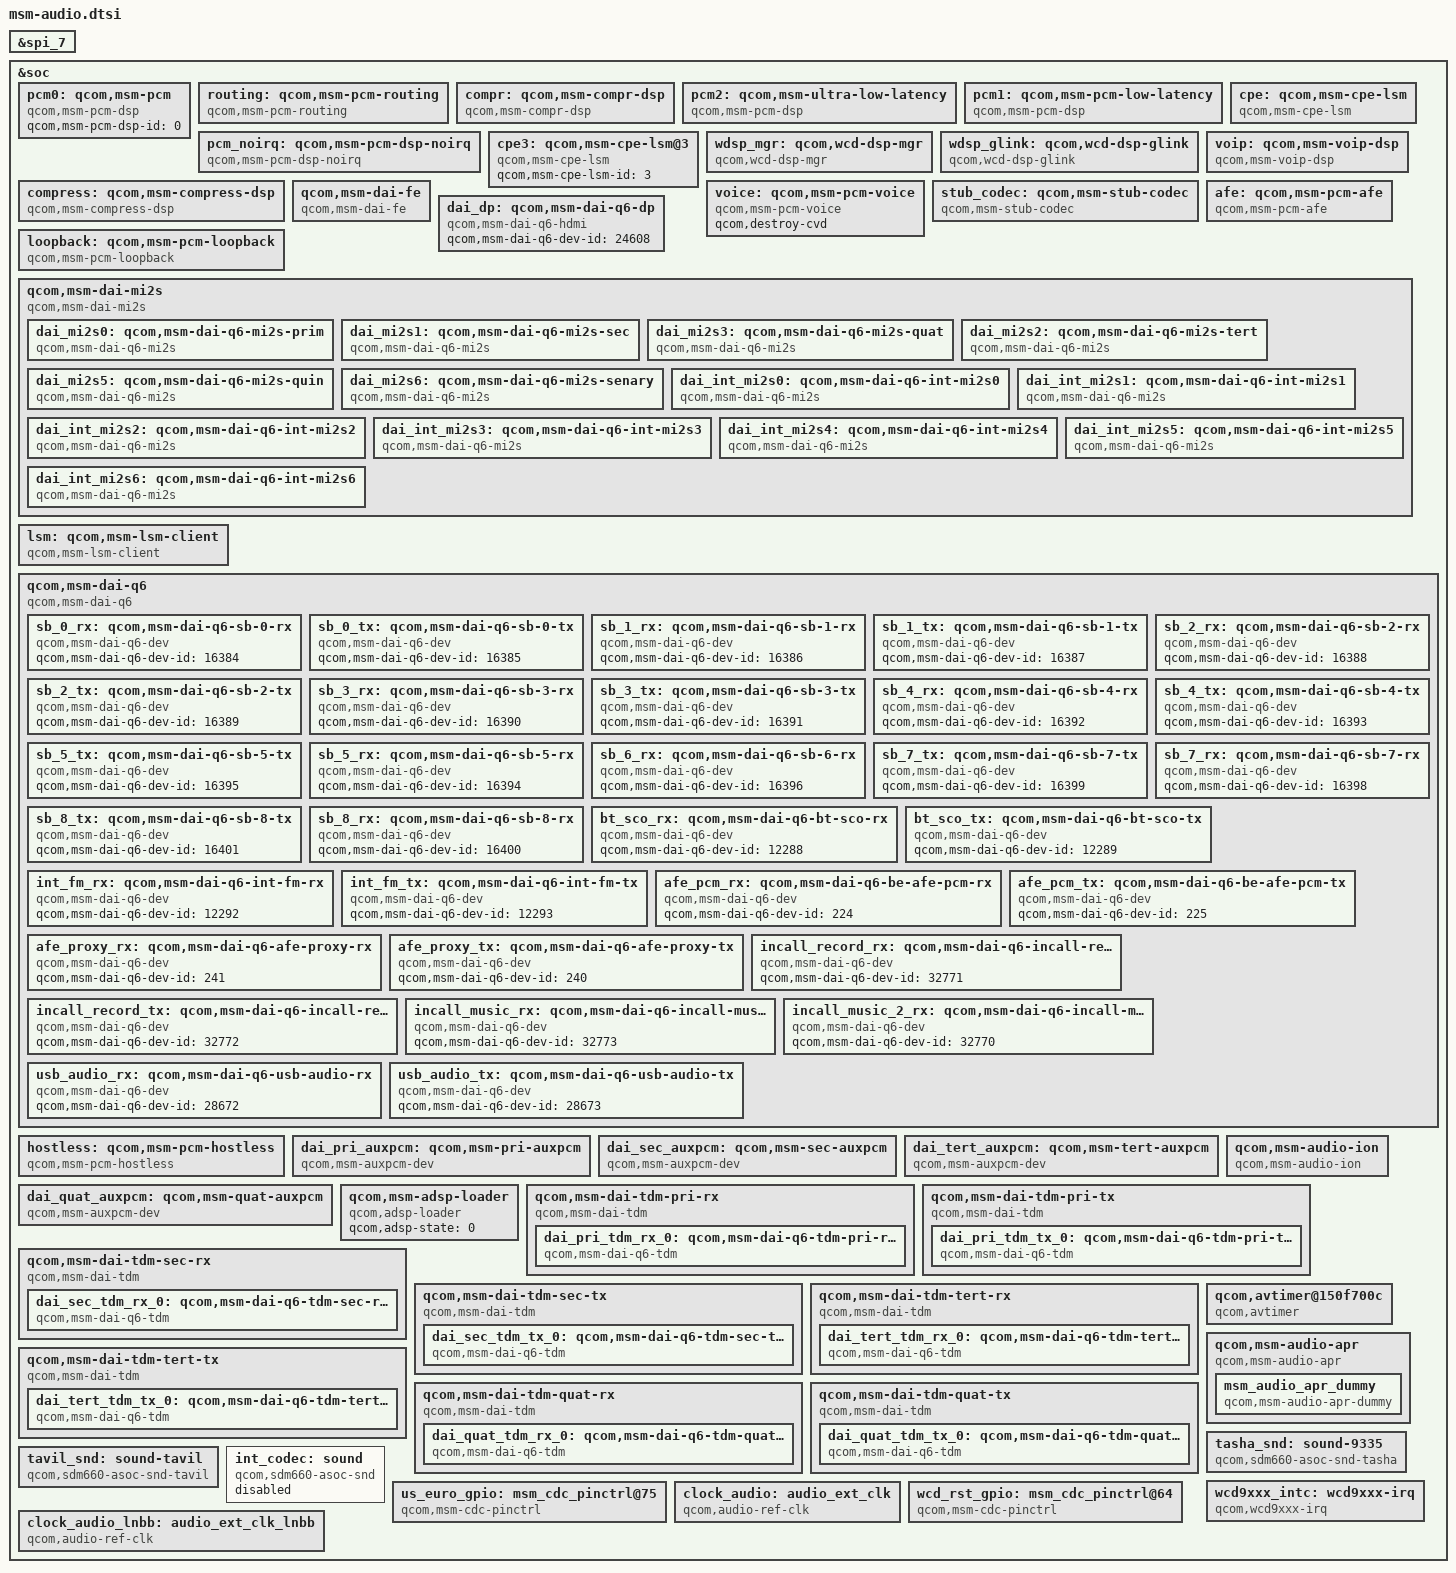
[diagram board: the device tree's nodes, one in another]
/*
 * Copyright (c) 2015-2017, 2019 The Linux Foundation. All rights reserved.
 *
 * This program is free software; you can redistribute it and/or modify
 * it under the terms of the GNU General Public License version 2 and
 * only version 2 as published by the Free Software Foundation.
 *
 * This program is distributed in the hope that it will be useful,
 * but WITHOUT ANY WARRANTY; without even the implied warranty of
 * MERCHANTABILITY or FITNESS FOR A PARTICULAR PURPOSE.  See the
 * GNU General Public License for more details.
 */

&spi_7 {
	status = "okay";
};

&soc {
	pcm0: qcom,msm-pcm {
		compatible = "qcom,msm-pcm-dsp";
		qcom,msm-pcm-dsp-id = <0>;
	};

	routing: qcom,msm-pcm-routing {
		compatible = "qcom,msm-pcm-routing";
	};

	compr: qcom,msm-compr-dsp {
		compatible = "qcom,msm-compr-dsp";
	};

	pcm2: qcom,msm-ultra-low-latency {
		compatible = "qcom,msm-pcm-dsp";
		qcom,msm-pcm-dsp-id = <2>;
		qcom,msm-pcm-low-latency;
		qcom,latency-level = "ultra";
	};

	pcm1: qcom,msm-pcm-low-latency {
		compatible = "qcom,msm-pcm-dsp";
		qcom,msm-pcm-dsp-id = <1>;
		qcom,msm-pcm-low-latency;
		qcom,latency-level = "regular";
	};

	pcm2: qcom,msm-ultra-low-latency {
		compatible = "qcom,msm-pcm-dsp";
		qcom,msm-pcm-dsp-id = <2>;
		qcom,msm-pcm-low-latency;
		qcom,latency-level = "ultra";
	};

	pcm_noirq: qcom,msm-pcm-dsp-noirq {
		compatible = "qcom,msm-pcm-dsp-noirq";
		qcom,msm-pcm-low-latency;
		qcom,latency-level = "ultra";
	};

	cpe: qcom,msm-cpe-lsm {
		compatible = "qcom,msm-cpe-lsm";
	};

	cpe3: qcom,msm-cpe-lsm@3 {
		compatible = "qcom,msm-cpe-lsm";
		qcom,msm-cpe-lsm-id = <3>;
	};

	wdsp_mgr: qcom,wcd-dsp-mgr {
		compatible = "qcom,wcd-dsp-mgr";
		qcom,wdsp-components = <&wcd934x_cdc 0>,
				       <&wcd_spi_0 1>,
				       <&glink_spi_xprt_wdsp 2>;
		qcom,img-filename = "cpe_9340";
	};

	wdsp_glink: qcom,wcd-dsp-glink {
		compatible = "qcom,wcd-dsp-glink";
	};

	compress: qcom,msm-compress-dsp {
		compatible = "qcom,msm-compress-dsp";
	};

	voip: qcom,msm-voip-dsp {
		compatible = "qcom,msm-voip-dsp";
	};

	voice: qcom,msm-pcm-voice {
		compatible = "qcom,msm-pcm-voice";
		qcom,destroy-cvd;
	};

	stub_codec: qcom,msm-stub-codec {
		compatible = "qcom,msm-stub-codec";
	};

	qcom,msm-dai-fe {
		compatible = "qcom,msm-dai-fe";
	};

	afe: qcom,msm-pcm-afe {
		compatible = "qcom,msm-pcm-afe";
	};

	dai_dp: qcom,msm-dai-q6-dp {
		compatible = "qcom,msm-dai-q6-hdmi";
		qcom,msm-dai-q6-dev-id = <24608>;
	};

	loopback: qcom,msm-pcm-loopback {
		compatible = "qcom,msm-pcm-loopback";
	};

	qcom,msm-dai-mi2s {
		compatible = "qcom,msm-dai-mi2s";
		dai_mi2s0: qcom,msm-dai-q6-mi2s-prim {
			compatible = "qcom,msm-dai-q6-mi2s";
			qcom,msm-dai-q6-mi2s-dev-id = <0>;
			qcom,msm-mi2s-rx-lines = <3>;
			qcom,msm-mi2s-tx-lines = <0>;
		};

		dai_mi2s1: qcom,msm-dai-q6-mi2s-sec {
			compatible = "qcom,msm-dai-q6-mi2s";
			qcom,msm-dai-q6-mi2s-dev-id = <1>;
			qcom,msm-mi2s-rx-lines = <1>;
			qcom,msm-mi2s-tx-lines = <0>;
		};

		dai_mi2s3: qcom,msm-dai-q6-mi2s-quat {
			compatible = "qcom,msm-dai-q6-mi2s";
			qcom,msm-dai-q6-mi2s-dev-id = <3>;
			qcom,msm-mi2s-rx-lines = <1>;
			qcom,msm-mi2s-tx-lines = <2>;
		};

		dai_mi2s2: qcom,msm-dai-q6-mi2s-tert {
			compatible = "qcom,msm-dai-q6-mi2s";
			qcom,msm-dai-q6-mi2s-dev-id = <2>;
			qcom,msm-mi2s-rx-lines = <0>;
			qcom,msm-mi2s-tx-lines = <3>;
		};

		dai_mi2s5: qcom,msm-dai-q6-mi2s-quin {
			compatible = "qcom,msm-dai-q6-mi2s";
			qcom,msm-dai-q6-mi2s-dev-id = <5>;
			qcom,msm-mi2s-rx-lines = <1>;
			qcom,msm-mi2s-tx-lines = <2>;
		};

		dai_mi2s6: qcom,msm-dai-q6-mi2s-senary {
			compatible = "qcom,msm-dai-q6-mi2s";
			qcom,msm-dai-q6-mi2s-dev-id = <6>;
			qcom,msm-mi2s-rx-lines = <0>;
			qcom,msm-mi2s-tx-lines = <3>;
		};

		dai_int_mi2s0: qcom,msm-dai-q6-int-mi2s0 {
			compatible = "qcom,msm-dai-q6-mi2s";
			qcom,msm-dai-q6-mi2s-dev-id = <7>;
			qcom,msm-mi2s-rx-lines = <3>;
			qcom,msm-mi2s-tx-lines = <0>;
		};

		dai_int_mi2s1: qcom,msm-dai-q6-int-mi2s1 {
			compatible = "qcom,msm-dai-q6-mi2s";
			qcom,msm-dai-q6-mi2s-dev-id = <8>;
			qcom,msm-mi2s-rx-lines = <3>;
			qcom,msm-mi2s-tx-lines = <0>;
		};

		dai_int_mi2s2: qcom,msm-dai-q6-int-mi2s2 {
			compatible = "qcom,msm-dai-q6-mi2s";
			qcom,msm-dai-q6-mi2s-dev-id = <9>;
			qcom,msm-mi2s-rx-lines = <0>;
			qcom,msm-mi2s-tx-lines = <3>;
		};

		dai_int_mi2s3: qcom,msm-dai-q6-int-mi2s3 {
			compatible = "qcom,msm-dai-q6-mi2s";
			qcom,msm-dai-q6-mi2s-dev-id = <10>;
			qcom,msm-mi2s-rx-lines = <0>;
			qcom,msm-mi2s-tx-lines = <3>;
		};

		dai_int_mi2s4: qcom,msm-dai-q6-int-mi2s4 {
			compatible = "qcom,msm-dai-q6-mi2s";
			qcom,msm-dai-q6-mi2s-dev-id = <11>;
			qcom,msm-mi2s-rx-lines = <3>;
			qcom,msm-mi2s-tx-lines = <0>;
		};

		dai_int_mi2s5: qcom,msm-dai-q6-int-mi2s5 {
			compatible = "qcom,msm-dai-q6-mi2s";
			qcom,msm-dai-q6-mi2s-dev-id = <12>;
			qcom,msm-mi2s-rx-lines = <0>;
			qcom,msm-mi2s-tx-lines = <3>;
		};

		dai_int_mi2s6: qcom,msm-dai-q6-int-mi2s6 {
			compatible = "qcom,msm-dai-q6-mi2s";
			qcom,msm-dai-q6-mi2s-dev-id = <13>;
			qcom,msm-mi2s-rx-lines = <0>;
			qcom,msm-mi2s-tx-lines = <3>;
		};
	};

	lsm: qcom,msm-lsm-client {
		compatible = "qcom,msm-lsm-client";
	};

	qcom,msm-dai-q6 {
		compatible = "qcom,msm-dai-q6";
		sb_0_rx: qcom,msm-dai-q6-sb-0-rx {
			compatible = "qcom,msm-dai-q6-dev";
			qcom,msm-dai-q6-dev-id = <16384>;
		};

		sb_0_tx: qcom,msm-dai-q6-sb-0-tx {
			compatible = "qcom,msm-dai-q6-dev";
			qcom,msm-dai-q6-dev-id = <16385>;
		};

		sb_1_rx: qcom,msm-dai-q6-sb-1-rx {
			compatible = "qcom,msm-dai-q6-dev";
			qcom,msm-dai-q6-dev-id = <16386>;
		};

		sb_1_tx: qcom,msm-dai-q6-sb-1-tx {
			compatible = "qcom,msm-dai-q6-dev";
			qcom,msm-dai-q6-dev-id = <16387>;
		};

		sb_2_rx: qcom,msm-dai-q6-sb-2-rx {
			compatible = "qcom,msm-dai-q6-dev";
			qcom,msm-dai-q6-dev-id = <16388>;
		};

		sb_2_tx: qcom,msm-dai-q6-sb-2-tx {
			compatible = "qcom,msm-dai-q6-dev";
			qcom,msm-dai-q6-dev-id = <16389>;
		};


		sb_3_rx: qcom,msm-dai-q6-sb-3-rx {
			compatible = "qcom,msm-dai-q6-dev";
			qcom,msm-dai-q6-dev-id = <16390>;
		};

		sb_3_tx: qcom,msm-dai-q6-sb-3-tx {
			compatible = "qcom,msm-dai-q6-dev";
			qcom,msm-dai-q6-dev-id = <16391>;
		};

		sb_4_rx: qcom,msm-dai-q6-sb-4-rx {
			compatible = "qcom,msm-dai-q6-dev";
			qcom,msm-dai-q6-dev-id = <16392>;
		};

		sb_4_tx: qcom,msm-dai-q6-sb-4-tx {
			compatible = "qcom,msm-dai-q6-dev";
			qcom,msm-dai-q6-dev-id = <16393>;
		};

		sb_5_tx: qcom,msm-dai-q6-sb-5-tx {
			compatible = "qcom,msm-dai-q6-dev";
			qcom,msm-dai-q6-dev-id = <16395>;
		};

		sb_5_rx: qcom,msm-dai-q6-sb-5-rx {
			compatible = "qcom,msm-dai-q6-dev";
			qcom,msm-dai-q6-dev-id = <16394>;
		};

		sb_6_rx: qcom,msm-dai-q6-sb-6-rx {
			compatible = "qcom,msm-dai-q6-dev";
			qcom,msm-dai-q6-dev-id = <16396>;
		};

		sb_7_tx: qcom,msm-dai-q6-sb-7-tx {
			compatible = "qcom,msm-dai-q6-dev";
			qcom,msm-dai-q6-dev-id = <16399>;
		};

		sb_7_rx: qcom,msm-dai-q6-sb-7-rx {
			compatible = "qcom,msm-dai-q6-dev";
			qcom,msm-dai-q6-dev-id = <16398>;
		};

		sb_8_tx: qcom,msm-dai-q6-sb-8-tx {
			compatible = "qcom,msm-dai-q6-dev";
			qcom,msm-dai-q6-dev-id = <16401>;
		};

		sb_8_rx: qcom,msm-dai-q6-sb-8-rx {
			compatible = "qcom,msm-dai-q6-dev";
			qcom,msm-dai-q6-dev-id = <16400>;
		};

		bt_sco_rx: qcom,msm-dai-q6-bt-sco-rx {
			compatible = "qcom,msm-dai-q6-dev";
			qcom,msm-dai-q6-dev-id = <12288>;
		};

		bt_sco_tx: qcom,msm-dai-q6-bt-sco-tx {
			compatible = "qcom,msm-dai-q6-dev";
			qcom,msm-dai-q6-dev-id = <12289>;
		};

		int_fm_rx: qcom,msm-dai-q6-int-fm-rx {
			compatible = "qcom,msm-dai-q6-dev";
			qcom,msm-dai-q6-dev-id = <12292>;
		};

		int_fm_tx: qcom,msm-dai-q6-int-fm-tx {
			compatible = "qcom,msm-dai-q6-dev";
			qcom,msm-dai-q6-dev-id = <12293>;
		};

		afe_pcm_rx: qcom,msm-dai-q6-be-afe-pcm-rx {
			compatible = "qcom,msm-dai-q6-dev";
			qcom,msm-dai-q6-dev-id = <224>;
		};

		afe_pcm_tx: qcom,msm-dai-q6-be-afe-pcm-tx {
			compatible = "qcom,msm-dai-q6-dev";
			qcom,msm-dai-q6-dev-id = <225>;
		};

		afe_proxy_rx: qcom,msm-dai-q6-afe-proxy-rx {
			compatible = "qcom,msm-dai-q6-dev";
			qcom,msm-dai-q6-dev-id = <241>;
		};

		afe_proxy_tx: qcom,msm-dai-q6-afe-proxy-tx {
			compatible = "qcom,msm-dai-q6-dev";
			qcom,msm-dai-q6-dev-id = <240>;
		};

		incall_record_rx: qcom,msm-dai-q6-incall-record-rx {
			compatible = "qcom,msm-dai-q6-dev";
			qcom,msm-dai-q6-dev-id = <32771>;
		};

		incall_record_tx: qcom,msm-dai-q6-incall-record-tx {
			compatible = "qcom,msm-dai-q6-dev";
			qcom,msm-dai-q6-dev-id = <32772>;
		};

		incall_music_rx: qcom,msm-dai-q6-incall-music-rx {
			compatible = "qcom,msm-dai-q6-dev";
			qcom,msm-dai-q6-dev-id = <32773>;
		};

		incall_music_2_rx: qcom,msm-dai-q6-incall-music-2-rx {
			compatible = "qcom,msm-dai-q6-dev";
			qcom,msm-dai-q6-dev-id = <32770>;
		};

		usb_audio_rx: qcom,msm-dai-q6-usb-audio-rx {
			compatible = "qcom,msm-dai-q6-dev";
			qcom,msm-dai-q6-dev-id = <28672>;
		};

		usb_audio_tx: qcom,msm-dai-q6-usb-audio-tx {
			compatible = "qcom,msm-dai-q6-dev";
			qcom,msm-dai-q6-dev-id = <28673>;
		};
	};

	hostless: qcom,msm-pcm-hostless {
		compatible = "qcom,msm-pcm-hostless";
	};

	dai_pri_auxpcm: qcom,msm-pri-auxpcm {
		compatible = "qcom,msm-auxpcm-dev";
		qcom,msm-cpudai-auxpcm-mode = <0>, <0>;
		qcom,msm-cpudai-auxpcm-sync = <1>, <1>;
		qcom,msm-cpudai-auxpcm-frame = <5>, <4>;
		qcom,msm-cpudai-auxpcm-quant = <2>, <2>;
		qcom,msm-cpudai-auxpcm-num-slots = <1>, <1>;
		qcom,msm-cpudai-auxpcm-slot-mapping = <1>, <1>;
		qcom,msm-cpudai-auxpcm-data = <0>, <0>;
		qcom,msm-cpudai-auxpcm-pcm-clk-rate = <2048000>, <2048000>;
		qcom,msm-auxpcm-interface = "primary";
		qcom,msm-cpudai-afe-clk-ver = <2>;
	};

	dai_sec_auxpcm: qcom,msm-sec-auxpcm {
		compatible = "qcom,msm-auxpcm-dev";
		qcom,msm-cpudai-auxpcm-mode = <0>, <0>;
		qcom,msm-cpudai-auxpcm-sync = <1>, <1>;
		qcom,msm-cpudai-auxpcm-frame = <5>, <4>;
		qcom,msm-cpudai-auxpcm-quant = <2>, <2>;
		qcom,msm-cpudai-auxpcm-num-slots = <1>, <1>;
		qcom,msm-cpudai-auxpcm-slot-mapping = <1>, <1>;
		qcom,msm-cpudai-auxpcm-data = <0>, <0>;
		qcom,msm-cpudai-auxpcm-pcm-clk-rate = <2048000>, <2048000>;
		qcom,msm-auxpcm-interface = "secondary";
		qcom,msm-cpudai-afe-clk-ver = <2>;
	};

	dai_tert_auxpcm: qcom,msm-tert-auxpcm {
		compatible = "qcom,msm-auxpcm-dev";
		qcom,msm-cpudai-auxpcm-mode = <0>, <0>;
		qcom,msm-cpudai-auxpcm-sync = <1>, <1>;
		qcom,msm-cpudai-auxpcm-frame = <5>, <4>;
		qcom,msm-cpudai-auxpcm-quant = <2>, <2>;
		qcom,msm-cpudai-auxpcm-num-slots = <1>, <1>;
		qcom,msm-cpudai-auxpcm-slot-mapping = <1>, <1>;
		qcom,msm-cpudai-auxpcm-data = <0>, <0>;
		qcom,msm-cpudai-auxpcm-pcm-clk-rate = <2048000>, <2048000>;
		qcom,msm-auxpcm-interface = "tertiary";
		qcom,msm-cpudai-afe-clk-ver = <2>;
	};

	dai_quat_auxpcm: qcom,msm-quat-auxpcm {
		compatible = "qcom,msm-auxpcm-dev";
		qcom,msm-cpudai-auxpcm-mode = <0>, <0>;
		qcom,msm-cpudai-auxpcm-sync = <1>, <1>;
		qcom,msm-cpudai-auxpcm-frame = <5>, <4>;
		qcom,msm-cpudai-auxpcm-quant = <2>, <2>;
		qcom,msm-cpudai-auxpcm-num-slots = <1>, <1>;
		qcom,msm-cpudai-auxpcm-slot-mapping = <1>, <1>;
		qcom,msm-cpudai-auxpcm-data = <0>, <0>;
		qcom,msm-cpudai-auxpcm-pcm-clk-rate = <2048000>, <2048000>;
		qcom,msm-auxpcm-interface = "quaternary";
		qcom,msm-cpudai-afe-clk-ver = <2>;
	};

	qcom,msm-audio-ion {
		compatible = "qcom,msm-audio-ion";
		qcom,smmu-version = <2>;
		qcom,smmu-enabled;
		iommus = <&lpass_q6_smmu 1>;
	};

	qcom,msm-adsp-loader {
		compatible = "qcom,adsp-loader";
		qcom,adsp-state = <0>;
	};

	qcom,msm-dai-tdm-pri-rx {
		compatible = "qcom,msm-dai-tdm";
		qcom,msm-cpudai-tdm-group-id = <37120>;
		qcom,msm-cpudai-tdm-group-num-ports = <1>;
		qcom,msm-cpudai-tdm-group-port-id = <36864>;
		qcom,msm-cpudai-tdm-clk-rate = <1536000>;
		qcom,msm-cpudai-tdm-clk-internal = <1>;
		qcom,msm-cpudai-tdm-sync-mode = <1>;
		qcom,msm-cpudai-tdm-sync-src = <1>;
		qcom,msm-cpudai-tdm-data-out = <0>;
		qcom,msm-cpudai-tdm-invert-sync = <1>;
		qcom,msm-cpudai-tdm-data-delay = <1>;
		dai_pri_tdm_rx_0: qcom,msm-dai-q6-tdm-pri-rx-0 {
			compatible = "qcom,msm-dai-q6-tdm";
			qcom,msm-cpudai-tdm-dev-id = <36864>;
			qcom,msm-cpudai-tdm-data-align = <0>;
		};
	};

	qcom,msm-dai-tdm-pri-tx {
		compatible = "qcom,msm-dai-tdm";
		qcom,msm-cpudai-tdm-group-id = <37121>;
		qcom,msm-cpudai-tdm-group-num-ports = <1>;
		qcom,msm-cpudai-tdm-group-port-id = <36865>;
		qcom,msm-cpudai-tdm-clk-rate = <1536000>;
		qcom,msm-cpudai-tdm-clk-internal = <1>;
		qcom,msm-cpudai-tdm-sync-mode = <1>;
		qcom,msm-cpudai-tdm-sync-src = <1>;
		qcom,msm-cpudai-tdm-data-out = <0>;
		qcom,msm-cpudai-tdm-invert-sync = <1>;
		qcom,msm-cpudai-tdm-data-delay = <1>;
		dai_pri_tdm_tx_0: qcom,msm-dai-q6-tdm-pri-tx-0 {
			compatible = "qcom,msm-dai-q6-tdm";
			qcom,msm-cpudai-tdm-dev-id = <36865>;
			qcom,msm-cpudai-tdm-data-align = <0>;
		};
	};

	qcom,msm-dai-tdm-sec-rx {
		compatible = "qcom,msm-dai-tdm";
		qcom,msm-cpudai-tdm-group-id = <37136>;
		qcom,msm-cpudai-tdm-group-num-ports = <1>;
		qcom,msm-cpudai-tdm-group-port-id = <36880>;
		qcom,msm-cpudai-tdm-clk-rate = <1536000>;
		qcom,msm-cpudai-tdm-clk-internal = <1>;
		qcom,msm-cpudai-tdm-sync-mode = <1>;
		qcom,msm-cpudai-tdm-sync-src = <1>;
		qcom,msm-cpudai-tdm-data-out = <0>;
		qcom,msm-cpudai-tdm-invert-sync = <1>;
		qcom,msm-cpudai-tdm-data-delay = <1>;
		dai_sec_tdm_rx_0: qcom,msm-dai-q6-tdm-sec-rx-0 {
			compatible = "qcom,msm-dai-q6-tdm";
			qcom,msm-cpudai-tdm-dev-id = <36880>;
			qcom,msm-cpudai-tdm-data-align = <0>;
		};
	};

	qcom,msm-dai-tdm-sec-tx {
		compatible = "qcom,msm-dai-tdm";
		qcom,msm-cpudai-tdm-group-id = <37137>;
		qcom,msm-cpudai-tdm-group-num-ports = <1>;
		qcom,msm-cpudai-tdm-group-port-id = <36881>;
		qcom,msm-cpudai-tdm-clk-rate = <1536000>;
		qcom,msm-cpudai-tdm-clk-internal = <1>;
		qcom,msm-cpudai-tdm-sync-mode = <1>;
		qcom,msm-cpudai-tdm-sync-src = <1>;
		qcom,msm-cpudai-tdm-data-out = <0>;
		qcom,msm-cpudai-tdm-invert-sync = <1>;
		qcom,msm-cpudai-tdm-data-delay = <1>;
		dai_sec_tdm_tx_0: qcom,msm-dai-q6-tdm-sec-tx-0 {
			compatible = "qcom,msm-dai-q6-tdm";
			qcom,msm-cpudai-tdm-dev-id = <36881>;
			qcom,msm-cpudai-tdm-data-align = <0>;
		};
	};

	qcom,msm-dai-tdm-tert-rx {
		compatible = "qcom,msm-dai-tdm";
		qcom,msm-cpudai-tdm-group-id = <37152>;
		qcom,msm-cpudai-tdm-group-num-ports = <1>;
		qcom,msm-cpudai-tdm-group-port-id = <36896>;
		qcom,msm-cpudai-tdm-clk-rate = <1536000>;
		qcom,msm-cpudai-tdm-clk-internal = <1>;
		qcom,msm-cpudai-tdm-sync-mode = <1>;
		qcom,msm-cpudai-tdm-sync-src = <1>;
		qcom,msm-cpudai-tdm-data-out = <0>;
		qcom,msm-cpudai-tdm-invert-sync = <1>;
		qcom,msm-cpudai-tdm-data-delay = <1>;
		dai_tert_tdm_rx_0: qcom,msm-dai-q6-tdm-tert-rx-0 {
			compatible = "qcom,msm-dai-q6-tdm";
			qcom,msm-cpudai-tdm-dev-id = <36896>;
			qcom,msm-cpudai-tdm-data-align = <0>;
		};
	};

	qcom,msm-dai-tdm-tert-tx {
		compatible = "qcom,msm-dai-tdm";
		qcom,msm-cpudai-tdm-group-id = <37153>;
		qcom,msm-cpudai-tdm-group-num-ports = <1>;
		qcom,msm-cpudai-tdm-group-port-id = <36897 >;
		qcom,msm-cpudai-tdm-clk-rate = <1536000>;
		qcom,msm-cpudai-tdm-clk-internal = <1>;
		qcom,msm-cpudai-tdm-sync-mode = <1>;
		qcom,msm-cpudai-tdm-sync-src = <1>;
		qcom,msm-cpudai-tdm-data-out = <0>;
		qcom,msm-cpudai-tdm-invert-sync = <1>;
		qcom,msm-cpudai-tdm-data-delay = <1>;
		dai_tert_tdm_tx_0: qcom,msm-dai-q6-tdm-tert-tx-0 {
			compatible = "qcom,msm-dai-q6-tdm";
			qcom,msm-cpudai-tdm-dev-id = <36897 >;
			qcom,msm-cpudai-tdm-data-align = <0>;
		};
	};

	qcom,msm-dai-tdm-quat-rx {
		compatible = "qcom,msm-dai-tdm";
		qcom,msm-cpudai-tdm-group-id = <37168>;
		qcom,msm-cpudai-tdm-group-num-ports = <1>;
		qcom,msm-cpudai-tdm-group-port-id = <36912>;
		qcom,msm-cpudai-tdm-clk-rate = <1536000>;
		qcom,msm-cpudai-tdm-clk-internal = <1>;
		qcom,msm-cpudai-tdm-sync-mode = <1>;
		qcom,msm-cpudai-tdm-sync-src = <1>;
		qcom,msm-cpudai-tdm-data-out = <0>;
		qcom,msm-cpudai-tdm-invert-sync = <1>;
		qcom,msm-cpudai-tdm-data-delay = <1>;
		dai_quat_tdm_rx_0: qcom,msm-dai-q6-tdm-quat-rx-0 {
			compatible = "qcom,msm-dai-q6-tdm";
			qcom,msm-cpudai-tdm-dev-id = <36912>;
			qcom,msm-cpudai-tdm-data-align = <0>;
		};
	};

	qcom,msm-dai-tdm-quat-tx {
		compatible = "qcom,msm-dai-tdm";
		qcom,msm-cpudai-tdm-group-id = <37169>;
		qcom,msm-cpudai-tdm-group-num-ports = <1>;
		qcom,msm-cpudai-tdm-group-port-id = <36913 >;
		qcom,msm-cpudai-tdm-clk-rate = <1536000>;
		qcom,msm-cpudai-tdm-clk-internal = <1>;
		qcom,msm-cpudai-tdm-sync-mode = <1>;
		qcom,msm-cpudai-tdm-sync-src = <1>;
		qcom,msm-cpudai-tdm-data-out = <0>;
		qcom,msm-cpudai-tdm-invert-sync = <1>;
		qcom,msm-cpudai-tdm-data-delay = <1>;
		dai_quat_tdm_tx_0: qcom,msm-dai-q6-tdm-quat-tx-0 {
			compatible = "qcom,msm-dai-q6-tdm";
			qcom,msm-cpudai-tdm-dev-id = <36913 >;
			qcom,msm-cpudai-tdm-data-align = <0>;
		};
	};

	qcom,avtimer@150f700c {
		compatible = "qcom,avtimer";
		reg = <0x150f700c 0x4>,
			<0x150f7010 0x4>;
		reg-names = "avtimer_lsb_addr", "avtimer_msb_addr";
		qcom,clk-div = <27>;
	};

	qcom,msm-audio-apr {
		compatible = "qcom,msm-audio-apr";
		msm_audio_apr_dummy {
			compatible = "qcom,msm-audio-apr-dummy";
		};
	};

	tasha_snd: sound-9335 {
		compatible = "qcom,sdm660-asoc-snd-tasha";
		qcom,model = "sdm660-tasha-snd-card";
		qcom,wcn-btfm;
		qcom,mi2s-audio-intf;
		qcom,auxpcm-audio-intf;
		qcom,ext-disp-audio-rx;
		qcom,msm-mi2s-master = <1>, <1>, <1>, <1>;
		qcom,audio-routing =
			"AIF4 VI", "MCLK",
			"RX_BIAS", "MCLK",
			"MADINPUT", "MCLK",
			"AMIC2", "MIC BIAS2",
			"MIC BIAS2", "Headset Mic",
			"AMIC3", "MIC BIAS2",
			"MIC BIAS2", "ANCRight Headset Mic",
			"AMIC4", "MIC BIAS2",
			"MIC BIAS2", "ANCLeft Headset Mic",
			"AMIC5", "MIC BIAS3",
			"MIC BIAS3", "Handset Mic",
			"AMIC6", "MIC BIAS4",
			"MIC BIAS4", "Analog Mic6",
			"DMIC0", "MIC BIAS1",
			"MIC BIAS1", "Digital Mic0",
			"DMIC1", "MIC BIAS1",
			"MIC BIAS1", "Digital Mic1",
			"DMIC2", "MIC BIAS3",
			"MIC BIAS3", "Digital Mic2",
			"DMIC3", "MIC BIAS3",
			"MIC BIAS3", "Digital Mic3",
			"DMIC4", "MIC BIAS4",
			"MIC BIAS4", "Digital Mic4",
			"DMIC5", "MIC BIAS4",
			"MIC BIAS4", "Digital Mic5",
			"SpkrLeft IN", "SPK1 OUT",
			"SpkrRight IN", "SPK2 OUT";

		qcom,msm-mbhc-hphl-swh = <1>;
		qcom,msm-mbhc-gnd-swh = <1>;
		qcom,us-euro-gpios = <&us_euro_gpio>;
		qcom,hph-en0-gpio = <&tasha_hph_en0>;
		qcom,hph-en1-gpio = <&tasha_hph_en1>;
		qcom,msm-mclk-freq = <9600000>;
		asoc-platform = <&pcm0>, <&pcm1>, <&pcm2>, <&voip>, <&voice>,
				<&loopback>, <&compress>, <&hostless>,
				<&afe>, <&lsm>, <&routing>, <&cpe>, <&compr>,
				<&pcm_noirq>, <&cpe3>;
		asoc-platform-names = "msm-pcm-dsp.0", "msm-pcm-dsp.1",
				      "msm-pcm-dsp.2", "msm-voip-dsp",
				      "msm-pcm-voice", "msm-pcm-loopback",
				      "msm-compress-dsp", "msm-pcm-hostless",
				      "msm-pcm-afe", "msm-lsm-client",
				      "msm-pcm-routing", "msm-cpe-lsm",
				      "msm-compr-dsp", "msm-pcm-dsp-noirq",
				      "msm-cpe-lsm.3";
		asoc-cpu = <&dai_dp>, <&dai_mi2s0>,
				<&dai_mi2s1>,
				<&dai_mi2s2>, <&dai_mi2s3>,
				<&dai_pri_auxpcm>, <&dai_sec_auxpcm>,
				<&dai_tert_auxpcm>, <&dai_quat_auxpcm>,
				<&sb_0_rx>, <&sb_0_tx>, <&sb_1_rx>, <&sb_1_tx>,
				<&sb_2_rx>, <&sb_2_tx>, <&sb_3_rx>, <&sb_3_tx>,
				<&sb_4_rx>, <&sb_4_tx>, <&sb_5_tx>,
				<&afe_pcm_rx>, <&afe_pcm_tx>, <&afe_proxy_rx>,
				<&afe_proxy_tx>, <&incall_record_rx>,
				<&incall_record_tx>, <&incall_music_rx>,
				<&incall_music_2_rx>, <&sb_5_rx>, <&sb_6_rx>,
				<&sb_7_rx>, <&sb_7_tx>, <&sb_8_tx>, <&sb_8_rx>,
				<&usb_audio_rx>, <&usb_audio_tx>,
				<&dai_pri_tdm_rx_0>, <&dai_pri_tdm_tx_0>,
				<&dai_sec_tdm_rx_0>, <&dai_sec_tdm_tx_0>,
				<&dai_tert_tdm_rx_0>, <&dai_tert_tdm_tx_0>,
				<&dai_quat_tdm_rx_0>, <&dai_quat_tdm_tx_0>;
		asoc-cpu-names = "msm-dai-q6-dp.24608", "msm-dai-q6-mi2s.0",
				"msm-dai-q6-mi2s.1",
				"msm-dai-q6-mi2s.2", "msm-dai-q6-mi2s.3",
				"msm-dai-q6-auxpcm.1", "msm-dai-q6-auxpcm.2",
				"msm-dai-q6-auxpcm.3", "msm-dai-q6-auxpcm.4",
				"msm-dai-q6-dev.16384", "msm-dai-q6-dev.16385",
				"msm-dai-q6-dev.16386", "msm-dai-q6-dev.16387",
				"msm-dai-q6-dev.16388", "msm-dai-q6-dev.16389",
				"msm-dai-q6-dev.16390", "msm-dai-q6-dev.16391",
				"msm-dai-q6-dev.16392", "msm-dai-q6-dev.16393",
				"msm-dai-q6-dev.16395", "msm-dai-q6-dev.224",
				"msm-dai-q6-dev.225", "msm-dai-q6-dev.241",
				"msm-dai-q6-dev.240", "msm-dai-q6-dev.32771",
				"msm-dai-q6-dev.32772", "msm-dai-q6-dev.32773",
				"msm-dai-q6-dev.32770", "msm-dai-q6-dev.16394",
				"msm-dai-q6-dev.16396", "msm-dai-q6-dev.16398",
				"msm-dai-q6-dev.16399", "msm-dai-q6-dev.16401",
				"msm-dai-q6-dev.16400", "msm-dai-q6-dev.28672",
				"msm-dai-q6-dev.28673", "msm-dai-q6-tdm.36864",
				"msm-dai-q6-tdm.36865", "msm-dai-q6-tdm.36880",
				"msm-dai-q6-tdm.36881", "msm-dai-q6-tdm.36896",
				"msm-dai-q6-tdm.36897", "msm-dai-q6-tdm.36912",
				"msm-dai-q6-tdm.36913";
		asoc-codec = <&stub_codec>, <&ext_disp_audio_codec>;
		asoc-codec-names = "msm-stub-codec.1",
					"msm-ext-disp-audio-codec-rx";
		qcom,wsa-max-devs = <2>;
		qcom,wsa-devs = <&wsa881x_211>, <&wsa881x_212>,
				<&wsa881x_213>, <&wsa881x_214>;
		qcom,wsa-aux-dev-prefix = "SpkrLeft", "SpkrRight",
					  "SpkrLeft", "SpkrRight";
	};

	tavil_snd: sound-tavil {
		compatible = "qcom,sdm660-asoc-snd-tavil";
		qcom,model = "sdm660-tavil-snd-card";
		qcom,wcn-btfm;
		qcom,mi2s-audio-intf;
		qcom,auxpcm-audio-intf;
		qcom,ext-disp-audio-rx;
		qcom,msm-mi2s-master = <1>, <1>, <1>, <1>;
		qcom,audio-routing =
			"AIF4 VI", "MCLK",
			"RX_BIAS", "MCLK",
			"MADINPUT", "MCLK",
			"AMIC2", "MIC BIAS2",
			"MIC BIAS2", "Headset Mic",
			"AMIC3", "MIC BIAS2",
			"MIC BIAS2", "ANCRight Headset Mic",
			"AMIC4", "MIC BIAS2",
			"MIC BIAS2", "ANCLeft Headset Mic",
			"AMIC5", "MIC BIAS3",
			"MIC BIAS3", "Handset Mic",
			"DMIC0", "MIC BIAS1",
			"MIC BIAS1", "Digital Mic0",
			"DMIC1", "MIC BIAS1",
			"MIC BIAS1", "Digital Mic1",
			"DMIC2", "MIC BIAS3",
			"MIC BIAS3", "Digital Mic2",
			"DMIC3", "MIC BIAS3",
			"MIC BIAS3", "Digital Mic3",
			"DMIC4", "MIC BIAS4",
			"MIC BIAS4", "Digital Mic4",
			"DMIC5", "MIC BIAS4",
			"MIC BIAS4", "Digital Mic5",
			"SpkrLeft IN", "SPK1 OUT",
			"SpkrRight IN", "SPK2 OUT";

		qcom,msm-mbhc-hphl-swh = <1>;
		qcom,msm-mbhc-gnd-swh = <1>;
		qcom,us-euro-gpios = <&tavil_us_euro_sw>;
		qcom,hph-en0-gpio = <&tavil_hph_en0>;
		qcom,hph-en1-gpio = <&tavil_hph_en1>;
		qcom,msm-mclk-freq = <9600000>;
		qcom,usbc-analog-en1_gpio = <&wcd_usbc_analog_en1_gpio>;
		qcom,usbc-analog-en2_n_gpio = <&wcd_usbc_analog_en2n_gpio>;
		asoc-platform = <&pcm0>, <&pcm1>, <&pcm2>, <&voip>, <&voice>,
				<&loopback>, <&compress>, <&hostless>,
				<&afe>, <&lsm>, <&routing>, <&cpe>, <&compr>,
				<&pcm_noirq>;
		asoc-platform-names = "msm-pcm-dsp.0", "msm-pcm-dsp.1",
				"msm-pcm-dsp.2", "msm-voip-dsp",
				"msm-pcm-voice", "msm-pcm-loopback",
				"msm-compress-dsp", "msm-pcm-hostless",
				"msm-pcm-afe", "msm-lsm-client",
				"msm-pcm-routing", "msm-cpe-lsm",
				"msm-compr-dsp", "msm-pcm-dsp-noirq";
		asoc-cpu = <&dai_dp>, <&dai_mi2s0>,
				<&dai_mi2s1>,
				<&dai_mi2s2>, <&dai_mi2s3>,
				<&dai_pri_auxpcm>, <&dai_sec_auxpcm>,
				<&dai_tert_auxpcm>, <&dai_quat_auxpcm>,
				<&sb_0_rx>, <&sb_0_tx>, <&sb_1_rx>, <&sb_1_tx>,
				<&sb_2_rx>, <&sb_2_tx>, <&sb_3_rx>, <&sb_3_tx>,
				<&sb_4_rx>, <&sb_4_tx>, <&sb_5_tx>,
				<&afe_pcm_rx>, <&afe_pcm_tx>, <&afe_proxy_rx>,
				<&afe_proxy_tx>, <&incall_record_rx>,
				<&incall_record_tx>, <&incall_music_rx>,
				<&incall_music_2_rx>, <&sb_5_rx>, <&sb_6_rx>,
				<&sb_7_rx>, <&sb_7_tx>, <&sb_8_tx>, <&sb_8_rx>,
				<&usb_audio_rx>, <&usb_audio_tx>,
				<&dai_pri_tdm_rx_0>, <&dai_pri_tdm_tx_0>,
				<&dai_sec_tdm_rx_0>, <&dai_sec_tdm_tx_0>,
				<&dai_tert_tdm_rx_0>, <&dai_tert_tdm_tx_0>,
				<&dai_quat_tdm_rx_0>, <&dai_quat_tdm_tx_0>;
		asoc-cpu-names = "msm-dai-q6-dp.24608", "msm-dai-q6-mi2s.0",
				"msm-dai-q6-mi2s.1",
				"msm-dai-q6-mi2s.2", "msm-dai-q6-mi2s.3",
				"msm-dai-q6-auxpcm.1", "msm-dai-q6-auxpcm.2",
				"msm-dai-q6-auxpcm.3", "msm-dai-q6-auxpcm.4",
				"msm-dai-q6-dev.16384", "msm-dai-q6-dev.16385",
				"msm-dai-q6-dev.16386", "msm-dai-q6-dev.16387",
				"msm-dai-q6-dev.16388", "msm-dai-q6-dev.16389",
				"msm-dai-q6-dev.16390", "msm-dai-q6-dev.16391",
				"msm-dai-q6-dev.16392", "msm-dai-q6-dev.16393",
				"msm-dai-q6-dev.16395", "msm-dai-q6-dev.224",
				"msm-dai-q6-dev.225", "msm-dai-q6-dev.241",
				"msm-dai-q6-dev.240", "msm-dai-q6-dev.32771",
				"msm-dai-q6-dev.32772", "msm-dai-q6-dev.32773",
				"msm-dai-q6-dev.32770", "msm-dai-q6-dev.16394",
				"msm-dai-q6-dev.16396", "msm-dai-q6-dev.16398",
				"msm-dai-q6-dev.16399", "msm-dai-q6-dev.16401",
				"msm-dai-q6-dev.16400", "msm-dai-q6-dev.28672",
				"msm-dai-q6-dev.28673", "msm-dai-q6-tdm.36864",
				"msm-dai-q6-tdm.36865", "msm-dai-q6-tdm.36880",
				"msm-dai-q6-tdm.36881", "msm-dai-q6-tdm.36896",
				"msm-dai-q6-tdm.36897", "msm-dai-q6-tdm.36912",
				"msm-dai-q6-tdm.36913";
		asoc-codec = <&stub_codec>, <&ext_disp_audio_codec>;
		asoc-codec-names = "msm-stub-codec.1",
					"msm-ext-disp-audio-codec-rx";
		qcom,wsa-max-devs = <2>;
		qcom,wsa-devs = <&wsa881x_0211>, <&wsa881x_0212>,
				<&wsa881x_0213>, <&wsa881x_0214>;
		qcom,wsa-aux-dev-prefix = "SpkrLeft", "SpkrRight",
					  "SpkrLeft", "SpkrRight";
	};

	int_codec: sound {
		status = "disabled";
		compatible = "qcom,sdm660-asoc-snd";
		qcom,model = "sdm660-snd-card";
		qcom,wcn-btfm;
		qcom,mi2s-audio-intf;
		qcom,auxpcm-audio-intf;
		qcom,ext-disp-audio-rx;
		qcom,msm-mi2s-master = <1>, <1>, <1>, <1>;
		qcom,msm-mclk-freq = <9600000>;
		qcom,msm-mbhc-hphl-swh = <1>;
		qcom,msm-mbhc-gnd-swh = <1>;
		qcom,msm-micbias2-ext-cap;
		qcom,msm-hs-micbias-type = "external";
		qcom,us-euro-gpios = <&us_euro_gpio>;
		qcom,cdc-pdm-gpios = <&cdc_pdm_gpios>;
		qcom,cdc-comp-gpios = <&cdc_comp_gpios>;
		qcom,cdc-dmic-gpios = <&cdc_dmic_gpios>;
		qcom,audio-routing =
			"RX_BIAS", "INT_MCLK0",
			"SPK_RX_BIAS", "INT_MCLK0",
			"INT_LDO_H", "INT_MCLK0",
			"RX_I2S_CLK", "INT_MCLK0",
			"TX_I2S_CLK", "INT_MCLK0",
			"MIC BIAS External", "Handset Mic",
			"MIC BIAS External2", "Headset Mic",
			"MIC BIAS External", "Secondary Mic",
			"AMIC1", "MIC BIAS External",
			"AMIC2", "MIC BIAS External2",
			"AMIC3", "MIC BIAS External",
			"DMIC1", "MIC BIAS External",
			"MIC BIAS External", "Digital Mic1",
			"DMIC2", "MIC BIAS External",
			"MIC BIAS External", "Digital Mic2",
			"DMIC3", "MIC BIAS External",
			"MIC BIAS External", "Digital Mic3",
			"DMIC4", "MIC BIAS External",
			"MIC BIAS External", "Digital Mic4",
			"SpkrLeft IN", "SPK1 OUT",
			"SpkrRight IN", "SPK2 OUT",
			"PDM_IN_RX1", "PDM_OUT_RX1",
			"PDM_IN_RX2", "PDM_OUT_RX2",
			"PDM_IN_RX3", "PDM_OUT_RX3",
			"ADC1_IN", "ADC1_OUT",
			"ADC2_IN", "ADC2_OUT",
			"ADC3_IN", "ADC3_OUT";

		asoc-platform = <&pcm0>, <&pcm1>, <&pcm2>, <&voip>, <&voice>,
				<&loopback>, <&compress>, <&hostless>,
				<&afe>, <&lsm>, <&routing>, <&compr>,
				<&pcm_noirq>;
		asoc-platform-names = "msm-pcm-dsp.0", "msm-pcm-dsp.1",
				"msm-pcm-dsp.2", "msm-voip-dsp",
				"msm-pcm-voice", "msm-pcm-loopback",
				"msm-compress-dsp", "msm-pcm-hostless",
				"msm-pcm-afe", "msm-lsm-client",
				"msm-pcm-routing", "msm-compr-dsp",
				"msm-pcm-dsp-noirq";
		asoc-cpu = <&dai_dp>, <&dai_mi2s0>,
				<&dai_mi2s1>,
				<&dai_mi2s2>, <&dai_mi2s3>,
				<&dai_int_mi2s0>, <&dai_int_mi2s1>,
				<&dai_int_mi2s2>, <&dai_int_mi2s3>,
				<&dai_int_mi2s4>, <&dai_int_mi2s5>,
				<&dai_pri_auxpcm>, <&dai_sec_auxpcm>,
				<&dai_tert_auxpcm>, <&dai_quat_auxpcm>,
				<&afe_pcm_rx>, <&afe_pcm_tx>, <&afe_proxy_rx>,
				<&afe_proxy_tx>, <&incall_record_rx>,
				<&incall_record_tx>, <&incall_music_rx>,
				<&incall_music_2_rx>, <&sb_7_rx>, <&sb_7_tx>,
				<&sb_8_tx>, <&sb_8_rx>,
				<&usb_audio_rx>, <&usb_audio_tx>,
				<&dai_pri_tdm_rx_0>, <&dai_pri_tdm_tx_0>,
				<&dai_sec_tdm_rx_0>, <&dai_sec_tdm_tx_0>,
				<&dai_tert_tdm_rx_0>, <&dai_tert_tdm_tx_0>,
				<&dai_quat_tdm_rx_0>, <&dai_quat_tdm_tx_0>;
		asoc-cpu-names = "msm-dai-q6-dp.24608", "msm-dai-q6-mi2s.0",
				"msm-dai-q6-mi2s.1",
				"msm-dai-q6-mi2s.2", "msm-dai-q6-mi2s.3",
				"msm-dai-q6-mi2s.7", "msm-dai-q6-mi2s.8",
				"msm-dai-q6-mi2s.9", "msm-dai-q6-mi2s.10",
				"msm-dai-q6-mi2s.11", "msm-dai-q6-mi2s.12",
				"msm-dai-q6-auxpcm.1", "msm-dai-q6-auxpcm.2",
				"msm-dai-q6-auxpcm.3", "msm-dai-q6-auxpcm.4",
				"msm-dai-q6-dev.224", "msm-dai-q6-dev.225",
				"msm-dai-q6-dev.241", "msm-dai-q6-dev.240",
				"msm-dai-q6-dev.32771", "msm-dai-q6-dev.32772",
				"msm-dai-q6-dev.32773", "msm-dai-q6-dev.32770",
				"msm-dai-q6-dev.16398", "msm-dai-q6-dev.16399",
				"msm-dai-q6-dev.16401", "msm-dai-q6-dev.16400",
				"msm-dai-q6-dev.28672", "msm-dai-q6-dev.28673",
				"msm-dai-q6-tdm.36864", "msm-dai-q6-tdm.36865",
				"msm-dai-q6-tdm.36880", "msm-dai-q6-tdm.36881",
				"msm-dai-q6-tdm.36896", "msm-dai-q6-tdm.36897",
				"msm-dai-q6-tdm.36912", "msm-dai-q6-tdm.36913";
		asoc-codec = <&stub_codec>, <&msm_digital_codec>,
				<&pmic_analog_codec>, <&msm_sdw_codec>,
				<&ext_disp_audio_codec>;
		asoc-codec-names = "msm-stub-codec.1", "msm-dig-codec",
					"analog-codec", "msm_sdw_codec",
					"msm-ext-disp-audio-codec-rx";

		qcom,wsa-max-devs = <2>;
		qcom,wsa-devs = <&wsa881x_211_en>, <&wsa881x_212_en>,
				<&wsa881x_213_en>, <&wsa881x_214_en>;
		qcom,wsa-aux-dev-prefix = "SpkrLeft", "SpkrRight",
					  "SpkrLeft", "SpkrRight";
	};

	us_euro_gpio: msm_cdc_pinctrl@75 {
		compatible = "qcom,msm-cdc-pinctrl";
		pinctrl-names = "aud_active", "aud_sleep";
		pinctrl-0 = <&wcd_gnd_mic_swap_active>;
		pinctrl-1 = <&wcd_gnd_mic_swap_idle>;
	};

	wcd9xxx_intc: wcd9xxx-irq {
		compatible = "qcom,wcd9xxx-irq";
		interrupt-controller;
		#interrupt-cells = <1>;
		interrupts = <0 177 0>;
		interrupt-names = "wcd_irq";
	};

	clock_audio: audio_ext_clk {
		compatible = "qcom,audio-ref-clk";
		qcom,audio-ref-clk-gpio = <&pm660_gpios 3 0>;
		clock-names = "osr_clk";
		clocks = <&clock_rpmcc RPM_DIV_CLK1>;
		qcom,node_has_rpm_clock;
		#clock-cells = <1>;
		qcom,codec-mclk-clk-freq = <11289600>;
		qcom,mclk-clk-reg = <0x15020018 0x0>;
		pinctrl-names = "sleep", "active";
		pinctrl-0 = <&lpi_mclk0_sleep>;
		pinctrl-1 = <&lpi_mclk0_active>;
	};

	clock_audio_lnbb: audio_ext_clk_lnbb {
		compatible = "qcom,audio-ref-clk";
		clock-names = "osr_clk";
		clocks = <&clock_rpmcc RPM_LN_BB_CLK2>;
		qcom,node_has_rpm_clock;
		#clock-cells = <1>;
	};

	wcd_rst_gpio: msm_cdc_pinctrl@64 {
		compatible = "qcom,msm-cdc-pinctrl";
		pinctrl-names = "aud_active", "aud_sleep";
		pinctrl-0 = <&lpi_cdc_reset_active>;
		pinctrl-1 = <&lpi_cdc_reset_sleep>;
		qcom,lpi-gpios;
	};
};
